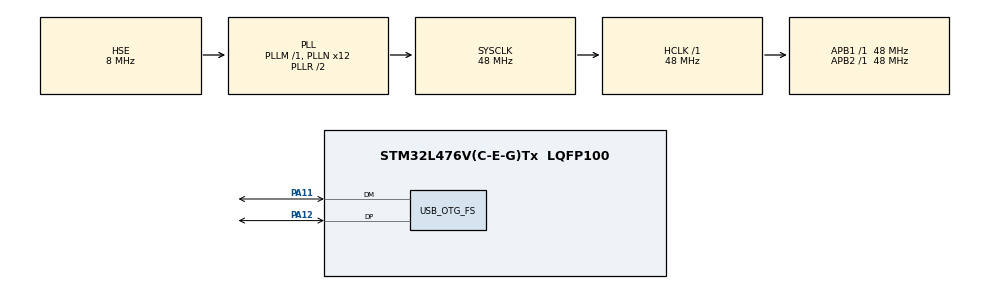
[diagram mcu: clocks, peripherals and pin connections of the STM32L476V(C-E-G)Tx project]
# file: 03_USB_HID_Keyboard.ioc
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Mcu.Family=STM32L4
Mcu.Name=STM32L476V(C-E-G)Tx
Mcu.Package=LQFP100
NVIC.OTG_FS_IRQn=true\:0\:0\:false\:false\:true\:false\:true\:true
NVIC.PriorityGroup=NVIC_PRIORITYGROUP_4
PA11.Mode=Device_Only
PA11.Signal=USB_OTG_FS_DM
PA12.Mode=Device_Only
PA12.Signal=USB_OTG_FS_DP
PH0-OSC_IN\ (PH0).Mode=HSE-External-Oscillator
PH0-OSC_IN\ (PH0).Signal=RCC_OSC_IN
PH1-OSC_OUT\ (PH1).Mode=HSE-External-Oscillator
PH1-OSC_OUT\ (PH1).Signal=RCC_OSC_OUT
ProjectManager.HeapSize=0x200
ProjectManager.StackSize=0x400
ProjectManager.TargetToolchain=STM32CubeIDE
RCC.ADCFreq_Value=32000000
RCC.AHBFreq_Value=48000000
RCC.APB1Freq_Value=48000000
RCC.APB1TimFreq_Value=48000000
RCC.APB2Freq_Value=48000000
RCC.APB2TimFreq_Value=48000000
RCC.CK48CLockSelection=RCC_USBCLKSOURCE_PLL
RCC.CortexFreq_Value=48000000
RCC.HCLKFreq_Value=48000000
RCC.HSE_VALUE=8000000
RCC.HSI_VALUE=16000000
RCC.LSE_VALUE=32768
RCC.MSI_VALUE=4000000
RCC.PLLN=12
RCC.PLLSourceVirtual=RCC_PLLSOURCE_HSE
RCC.PREFETCH_ENABLE=1
RCC.SYSCLKFreq_VALUE=48000000
RCC.SYSCLKSource=RCC_SYSCLKSOURCE_PLLCLK
RCC.USBFreq_Value=48000000
RCC.VCOOutputFreq_Value=96000000
USB_DEVICE.CLASS_NAME_FS=HID
USB_DEVICE.VirtualMode=Hid
USB_DEVICE.VirtualModeFS=Hid_FS
USB_OTG_FS.VirtualMode=Device_Only
VP_USB_DEVICE_VS_USB_DEVICE_HID_FS.Mode=HID_FS
board=STM32L476G-DISCO

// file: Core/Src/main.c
/* USER CODE BEGIN Header */
/**
  ******************************************************************************
  * @file           : main.c
  * @brief          : Main program body
  ******************************************************************************
  * @attention
  *
  * Copyright (c) 2024 STMicroelectronics.
  * All rights reserved.
  *
  * This software is licensed under terms that can be found in the LICENSE file
  * in the root directory of this software component.
  * If no LICENSE file comes with this software, it is provided AS-IS.
  *
  ******************************************************************************
  */
/* USER CODE END Header */
#include "main.h"
#include "usb_device.h"

/* USER CODE BEGIN Includes */
#include "usbd_hid.h"
#include "string.h"
/* USER CODE END Includes */

/* USER CODE BEGIN PV */
extern USBD_HandleTypeDef hUsbDeviceFS;

/* structure for keyboard input report */
typedef struct
{
	uint8_t MODIFIER;
	uint8_t RESERVED;
	uint8_t KEYCODE1;
	uint8_t KEYCODE2;
	uint8_t KEYCODE3;
	uint8_t KEYCODE4;
	uint8_t KEYCODE5;
	uint8_t KEYCODE6;
}KeyBoardReport;

KeyBoardReport HIDkeyBoard = {0,0,0,0,0,0,0,0};

char Msg_Buf[100] = {0};

/* USER CODE END PV */

void SystemClock_Config(void);
static void MX_GPIO_Init(void);

/* USER CODE BEGIN 0 */

   /* To print the contents of msg buf */
/*
void KeyBoardPrint(char *data,uint16_t length)
{
	for(uint16_t count=0;count<length;count++)
	{
		if(data[count]>=0x41 && data[count]<=0x5A)
		{
			HIDkeyBoard.MODIFIER=0x02;
			HIDkeyBoard.KEYCODE1=data[count]-0x3D;
			USBD_HID_SendReport(&hUsbDeviceFS,&HIDkeyBoard,sizeof(HIDkeyBoard));
			HAL_Delay(15);
			HIDkeyBoard.MODIFIER=0x00;
			HIDkeyBoard.KEYCODE1=0x00;
			USBD_HID_SendReport(&hUsbDeviceFS,&HIDkeyBoard,sizeof(HIDkeyBoard));
		}
		else if(data[count]>=0x61 && data[count]<=0x7A)
		{
			HIDkeyBoard.KEYCODE1=data[count]-0x5D;
			USBD_HID_SendReport(&hUsbDeviceFS,&HIDkeyBoard,sizeof(HIDkeyBoard));
			HAL_Delay(15);
			HIDkeyBoard.KEYCODE1=0x00;
			USBD_HID_SendReport(&hUsbDeviceFS,&HIDkeyBoard,sizeof(HIDkeyBoard));
		}
		else if(data[count]==0x20)
		{
			HIDkeyBoard.KEYCODE1=0x2C;
			USBD_HID_SendReport(&hUsbDeviceFS,&HIDkeyBoard,sizeof(HIDkeyBoard));
			HAL_Delay(15);
			HIDkeyBoard.KEYCODE1=0x00;
			USBD_HID_SendReport(&hUsbDeviceFS,&HIDkeyBoard,sizeof(HIDkeyBoard));
		}
		else if(data[count]==0x0A)
		{
			HIDkeyBoard.KEYCODE1=0x28;
			USBD_HID_SendReport(&hUsbDeviceFS,&HIDkeyBoard,sizeof(HIDkeyBoard));
			HAL_Delay(15);
			HIDkeyBoard.KEYCODE1=0x00;
			USBD_HID_SendReport(&hUsbDeviceFS,&HIDkeyBoard,sizeof(HIDkeyBoard));
		}
		HAL_Delay(25);
	}
}
*/

         /* print the contents of msg buf */

void KeyBoardPrint(char *data, uint16_t length) {
    for (uint16_t count = 0; count < length; count++)
    {
        if (data[count] >= 0x41 && data[count] <= 0x5A)	//uppercase A - Z
        {
            HIDkeyBoard.MODIFIER = 0x02;  //print capital letters
            HIDkeyBoard.KEYCODE1 = data[count] - 0x3D;
        }
        else if(data[count] >= 0x61 && data[count] <= 0x7A)	//lowercase a - z
        {
            HIDkeyBoard.KEYCODE1 = data[count] - 0x5D;
        }
        else if (data[count] == 0x20)		//space
        {
            HIDkeyBoard.KEYCODE1 = 0x2C;
        }
        else if (data[count] == 0x0A)		//new line (enter)
        {
            HIDkeyBoard.KEYCODE1 = 0x28;
        }
        else if (data[count] == 0x2C)		//comma(,)
        {
        	HIDkeyBoard.KEYCODE1 = 0x36;
        }
        else
        {
            HIDkeyBoard.KEYCODE1 = 0x00;
        }

        USBD_HID_SendReport(&hUsbDeviceFS, &HIDkeyBoard, sizeof(HIDkeyBoard));
        HAL_Delay(50);

        HIDkeyBoard.MODIFIER = 0x00;
        HIDkeyBoard.KEYCODE1 = 0x00;
        USBD_HID_SendReport(&hUsbDeviceFS, &HIDkeyBoard, sizeof(HIDkeyBoard));
        HAL_Delay(50);
    }
}
/* USER CODE END 0 */

int main(void)
{

  /* MCU Configuration--------------------------------------------------------*/

  /* Reset of all peripherals, Initializes the Flash interface and the Systick. */
  HAL_Init();

  /* Configure the system clock */
  SystemClock_Config();

  /* Initialize all configured peripherals */
  MX_GPIO_Init();
  MX_USB_DEVICE_Init();
  /* USER CODE BEGIN 2 */

  /* store the msg into buf */
  sprintf(Msg_Buf, "Hii, this is Pratham\r\n");

  /* USER CODE END 2 */

  /* Infinite loop */
  while (1)
  {

    /* USER CODE BEGIN 3 */

	  /* printing ABC using Keyboard */
	  /*
	  HIDkeyBoard.MODIFIER = 0x02;	//print char in capital
	  HIDkeyBoard.KEYCODE1 = 0x04;	//Print 'A'
	  HIDkeyBoard.KEYCODE2 = 0x05;	//print 'B'
	  HIDkeyBoard.KEYCODE3 = 0x06;	//print 'C'
	  USBD_HID_SendReport(&hUsbDeviceFS, &HIDkeyBoard, sizeof(HIDkeyBoard));
	  HAL_Delay(50);

	  HIDkeyBoard.MODIFIER = 0x00;	//Release Shift
	  HIDkeyBoard.KEYCODE1 = 0x00;	//Release key
	  HIDkeyBoard.KEYCODE2 = 0x00;	//Release key
	  HIDkeyBoard.KEYCODE3 = 0x00;	//Release key
	  USBD_HID_SendReport(&hUsbDeviceFS, &HIDkeyBoard, sizeof(HIDkeyBoard));
	  HAL_Delay(1000)
	  */

	  /*
	  HIDkeyBoard.MODIFIER = 0x02;		//print char in capital
	  HIDkeyBoard.KEYCODE1 = 0x13;		//print 'P'
	  HIDkeyBoard.KEYCODE2 = 0x15;		//print 'R'
	  HIDkeyBoard.KEYCODE3 = 0x04;		//print 'A'
	  HIDkeyBoard.KEYCODE4 = 0x17;		//print 'T'
	  HIDkeyBoard.KEYCODE5 = 0x0B;		//print 'H'
	  USBD_HID_SendReport(&hUsbDeviceFS, &HIDkeyBoard, sizeof(HIDkeyBoard));
	  HAL_Delay(50);

	  HIDkeyBoard.MODIFIER = 0x00;		//Release shift
	  HIDkeyBoard.KEYCODE1 = 0x00;		//Release Key
	  HIDkeyBoard.KEYCODE2 = 0x00;		//Release Key
	  HIDkeyBoard.KEYCODE3 = 0x00;		//Release Key
	  HIDkeyBoard.KEYCODE4 = 0x00;		//Release Key
	  HIDkeyBoard.KEYCODE5 = 0x00;		//Release Key
	  USBD_HID_SendReport(&hUsbDeviceFS, &HIDkeyBoard, sizeof(HIDkeyBoard));
	  HAL_Delay(50);

	  HIDkeyBoard.MODIFIER = 0x02;		//print char in capital
	  HIDkeyBoard.KEYCODE1 = 0x04;		//print 'A'
	  HIDkeyBoard.KEYCODE2 = 0x10;		//print 'M'
	  HIDkeyBoard.KEYCODE3 = 0x28;		//press Enter
	  USBD_HID_SendReport(&hUsbDeviceFS, &HIDkeyBoard, sizeof(HIDkeyBoard));
	  HAL_Delay(50);

	  HIDkeyBoard.MODIFIER = 0x00;		//Release shift
	  HIDkeyBoard.KEYCODE1 = 0x00;		//Release Key
	  HIDkeyBoard.KEYCODE2 = 0x00;		//Release Key
	  HIDkeyBoard.KEYCODE3 = 0x00;		//Release Key
	  USBD_HID_SendReport(&hUsbDeviceFS, &HIDkeyBoard, sizeof(HIDkeyBoard));
	  HAL_Delay(50);
	  */

	  /* call the function to print the msg using keyboard */
	  KeyBoardPrint(Msg_Buf, strlen(Msg_Buf));
	  HAL_Delay(1000);

  }
  /* USER CODE END 3 */
}

void SystemClock_Config(void)
{
  RCC_OscInitTypeDef RCC_OscInitStruct = {0};
  RCC_ClkInitTypeDef RCC_ClkInitStruct = {0};

  /** Configure the main internal regulator output voltage
  */
  if (HAL_PWREx_ControlVoltageScaling(PWR_REGULATOR_VOLTAGE_SCALE1) != HAL_OK)
  {
    Error_Handler();
  }

  /** Initializes the RCC Oscillators according to the specified parameters
  * in the RCC_OscInitTypeDef structure.
  */
  RCC_OscInitStruct.OscillatorType = RCC_OSCILLATORTYPE_HSE;
  RCC_OscInitStruct.HSEState = RCC_HSE_ON;
  RCC_OscInitStruct.PLL.PLLState = RCC_PLL_ON;
  RCC_OscInitStruct.PLL.PLLSource = RCC_PLLSOURCE_HSE;
  RCC_OscInitStruct.PLL.PLLM = 1;
  RCC_OscInitStruct.PLL.PLLN = 12;
  RCC_OscInitStruct.PLL.PLLP = RCC_PLLP_DIV7;
  RCC_OscInitStruct.PLL.PLLQ = RCC_PLLQ_DIV2;
  RCC_OscInitStruct.PLL.PLLR = RCC_PLLR_DIV2;
  if (HAL_RCC_OscConfig(&RCC_OscInitStruct) != HAL_OK)
  {
    Error_Handler();
  }

  /** Initializes the CPU, AHB and APB buses clocks
  */
  RCC_ClkInitStruct.ClockType = RCC_CLOCKTYPE_HCLK|RCC_CLOCKTYPE_SYSCLK
                              |RCC_CLOCKTYPE_PCLK1|RCC_CLOCKTYPE_PCLK2;
  RCC_ClkInitStruct.SYSCLKSource = RCC_SYSCLKSOURCE_PLLCLK;
  RCC_ClkInitStruct.AHBCLKDivider = RCC_SYSCLK_DIV1;
  RCC_ClkInitStruct.APB1CLKDivider = RCC_HCLK_DIV1;
  RCC_ClkInitStruct.APB2CLKDivider = RCC_HCLK_DIV1;

  if (HAL_RCC_ClockConfig(&RCC_ClkInitStruct, FLASH_LATENCY_2) != HAL_OK)
  {
    Error_Handler();
  }
}

static void MX_GPIO_Init(void)
{

  /* GPIO Ports Clock Enable */
  __HAL_RCC_GPIOH_CLK_ENABLE();
  __HAL_RCC_GPIOA_CLK_ENABLE();

}

void Error_Handler(void)
{
  __disable_irq();
  while (1)
  {
  }
}
